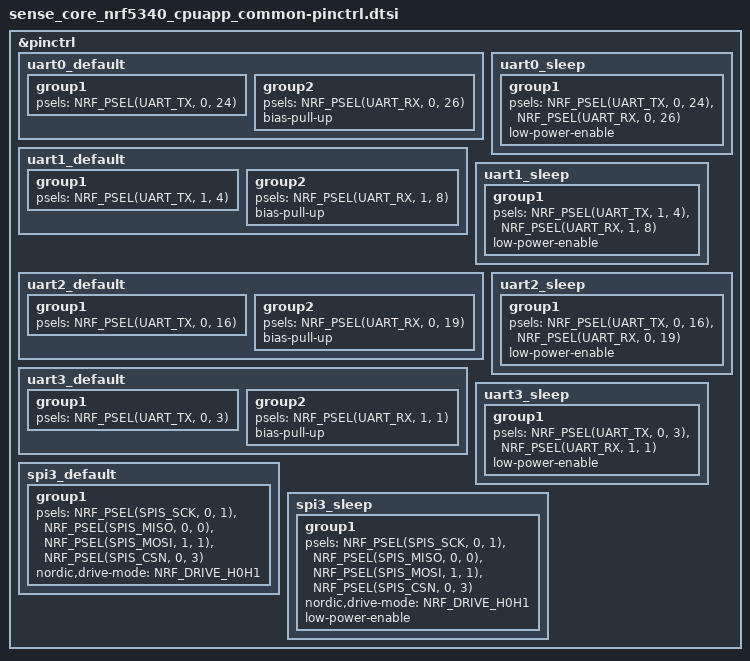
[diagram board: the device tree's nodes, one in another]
&pinctrl {
	uart0_default: uart0_default {
		group1 {
			psels = <NRF_PSEL(UART_TX, 0, 24)>;
		};
		group2 {
			psels = <NRF_PSEL(UART_RX, 0, 26)>;
			bias-pull-up;
		};
	};

	uart0_sleep: uart0_sleep {
		group1 {
			psels = <NRF_PSEL(UART_TX, 0, 24)>,
				<NRF_PSEL(UART_RX, 0, 26)>;
			low-power-enable;
		};
	};

	uart1_default: uart1_default {
		group1 {
			psels = <NRF_PSEL(UART_TX, 1, 4)>;
		};
		group2 {
			psels = <NRF_PSEL(UART_RX, 1, 8)>;
			bias-pull-up;
		};
	};

	uart1_sleep: uart1_sleep {
		group1 {
			psels = <NRF_PSEL(UART_TX, 1, 4)>,
				<NRF_PSEL(UART_RX, 1, 8)>;
			low-power-enable;
		};
	};

	uart2_default: uart2_default {
		group1 {
			psels = <NRF_PSEL(UART_TX, 0, 16)>;
		};
		group2 {
			psels = <NRF_PSEL(UART_RX, 0, 19)>;
			bias-pull-up;
		};
	};

	uart2_sleep: uart2_sleep {
		group1 {
			psels = <NRF_PSEL(UART_TX, 0, 16)>,
				<NRF_PSEL(UART_RX, 0, 19)>;
			low-power-enable;
		};
	};

	uart3_default: uart3_default {
		group1 {
			psels = <NRF_PSEL(UART_TX, 0, 3)>;
		};
		group2 {
			psels = <NRF_PSEL(UART_RX, 1, 1)>;
			bias-pull-up;
		};
	};

	uart3_sleep: uart3_sleep {
		group1 {
			psels = <NRF_PSEL(UART_TX, 0, 3)>,
				<NRF_PSEL(UART_RX, 1, 1)>;
			low-power-enable;
		};
	};

	spi3_default: spi3_default {
		group1 {
			psels = <NRF_PSEL(SPIS_SCK, 0, 1)>,
				<NRF_PSEL(SPIS_MISO, 0, 0)>,
				<NRF_PSEL(SPIS_MOSI, 1, 1)>,
				<NRF_PSEL(SPIS_CSN, 0, 3)>;
			nordic,drive-mode = <NRF_DRIVE_H0H1>;
		};
	};

	spi3_sleep: spi3_sleep {
		group1 {
			psels = <NRF_PSEL(SPIS_SCK, 0, 1)>,
				<NRF_PSEL(SPIS_MISO, 0, 0)>,
				<NRF_PSEL(SPIS_MOSI, 1, 1)>,
				<NRF_PSEL(SPIS_CSN, 0, 3)>;
			nordic,drive-mode = <NRF_DRIVE_H0H1>;
			low-power-enable;
		};
	};

};
